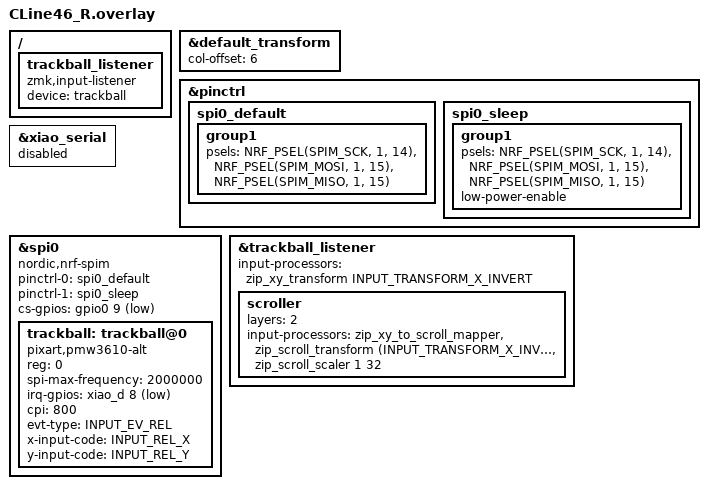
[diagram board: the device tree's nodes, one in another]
#include "CLine46.dtsi"
#include <zephyr/dt-bindings/input/input-event-codes.h>
#include <input/processors.dtsi>

&default_transform {
    col-offset = <6>;
};


/ {
    trackball_listener {
        status = "okay";
        compatible = "zmk,input-listener";
        device = <&trackball>;
    };
};

&pinctrl {
    spi0_default: spi0_default {
        group1 {
            psels = <NRF_PSEL(SPIM_SCK, 1, 14)>,
                <NRF_PSEL(SPIM_MOSI, 1, 15)>,
                <NRF_PSEL(SPIM_MISO, 1, 15)>;
        };
    };

    spi0_sleep: spi0_sleep {
        group1 {
            psels = <NRF_PSEL(SPIM_SCK, 1, 14)>,
                <NRF_PSEL(SPIM_MOSI, 1, 15)>,
                <NRF_PSEL(SPIM_MISO, 1, 15)>;
            low-power-enable;
        };
    };
};


&xiao_serial { status = "disabled"; };

&spi0 {
    status = "okay";
    compatible = "nordic,nrf-spim";
    pinctrl-0 = <&spi0_default>;
    pinctrl-1 = <&spi0_sleep>;
    pinctrl-names = "default", "sleep";
    cs-gpios = <&gpio0 9 GPIO_ACTIVE_LOW>;  // P0.09を指定(CS)

    trackball: trackball@0 {
        status = "okay";
        compatible = "pixart,pmw3610-alt";
        reg = <0>;
        spi-max-frequency = <2000000>;
        irq-gpios = <&xiao_d 8 (GPIO_ACTIVE_LOW | GPIO_PULL_UP)>;
        cpi = <800>;
        //swap-xy;
        evt-type = <INPUT_EV_REL>;
        x-input-code = <INPUT_REL_X>;
        y-input-code = <INPUT_REL_Y>;
    };
};

// Overrides for the input listener node
&trackball_listener {
    status = "okay";
    input-processors =
        <&zip_xy_transform INPUT_TRANSFORM_X_INVERT>;       // X軸反転

    scroller {
        layers = <2>;
        input-processors =
            <&zip_xy_to_scroll_mapper>,                                                     // スクロールモードに変更
            <&zip_scroll_transform (INPUT_TRANSFORM_X_INVERT | INPUT_TRANSFORM_Y_INVERT)>,  // スクロールのX軸・Y軸反転
            <&zip_scroll_scaler 1 32>;                                                      // スクロール量を1/32倍
    };
};
